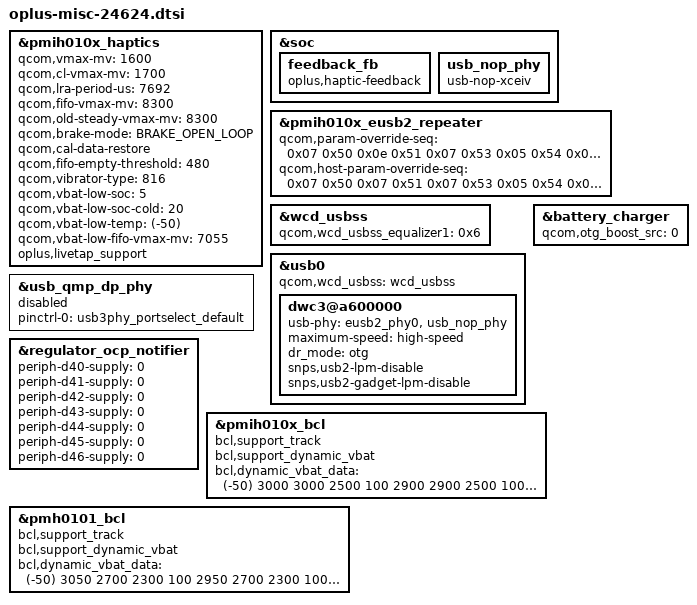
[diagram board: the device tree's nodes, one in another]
&pmih010x_haptics {
	qcom,vmax-mv = <1600>;
	qcom,cl-vmax-mv = <1700>;
	qcom,lra-period-us = <7692>;
	qcom,fifo-vmax-mv = <8300>;
	qcom,old-steady-vmax-mv = <8300>;
	qcom,brake-mode = <BRAKE_OPEN_LOOP>;
	qcom,cal-data-restore;
	qcom,fifo-empty-threshold = <480>;
	qcom,vibrator-type = <816>;//0816B
	qcom,vbat-low-soc = <5>;
	qcom,vbat-low-soc-cold = <20>;
	qcom,vbat-low-temp = <(-50)>;/*-5C*/
	qcom,vbat-low-fifo-vmax-mv = <7055>;
	oplus,livetap_support;
};

&soc {
	feedback_fb: feedback_fb {
		compatible = "oplus,haptic-feedback";
	};
};

&pmih010x_eusb2_repeater {
	qcom,param-override-seq = <0x07 0x50 0x0e 0x51 0x07 0x53 0x05 0x54 0x01 0x55 0x07 0x57>;
	qcom,host-param-override-seq = <0x07 0x50 0x07 0x51 0x07 0x53 0x05 0x54 0x00 0x55 0x03 0x57>;
};

&wcd_usbss {
	qcom,wcd_usbss_equalizer1 = /bits/ 8 <0x6>;
};

&soc {
	usb_nop_phy: usb_nop_phy {
		compatible = "usb-nop-xceiv";
	};
};

&usb0 {
	qcom,wcd_usbss = <&wcd_usbss>;
	dwc3@a600000 {
		usb-phy = <&eusb2_phy0>, <&usb_nop_phy>;
		maximum-speed = "high-speed";
		dr_mode = "otg";
		snps,usb2-lpm-disable;
		snps,usb2-gadget-lpm-disable;
	};
};

&usb_qmp_dp_phy {
	pinctrl-names = "default";
	pinctrl-0 = <&usb3phy_portselect_default>;
	status = "disabled";
};

&battery_charger {
	qcom,otg_boost_src = <0>; /* 0:plat_pmic 1:external */
};

&regulator_ocp_notifier {
	periph-d40-supply = <0>;
	periph-d41-supply = <0>;
	periph-d42-supply = <0>;
	periph-d43-supply = <0>;
	periph-d44-supply = <0>;
	periph-d45-supply = <0>;
	periph-d46-supply = <0>;
};
&pmih010x_bcl {
    bcl,support_track;
    bcl,support_dynamic_vbat;
    bcl,dynamic_vbat_data = <(-50) 3000 3000 2500
                100 2900 2900 2500
                1000 2800 2800 2500>;
};

&pmh0101_bcl {
    bcl,support_track;
    bcl,support_dynamic_vbat;
    bcl,dynamic_vbat_data = <(-50) 3050 2700 2300
                100 2950 2700 2300
                1000 2850 2700 2300>;
};
